# f29h85x_wadi_oper_sss_regs register map
Vendor: Texas Instruments
Peripheral module from a debugger description file (folder C29).
Registers are 32-bit, read-write, no defined reset value unless marked. A register's access mark holds for its fields unless they carry their own. Offsets are as the file gives them; lines under a group give offsets from that group; [hi:lo] are bit positions; {n}, {i} and the like mark numbered series; 'fields as' and 'values as' point back to an identical list; <NAME> marks a mode.

## WADI_OPER_SSS_REGS — WADI OPER SSS Registers
0x00 BASETIMERLOW ro — Read only value for lower word of the base timer.
  [31:0] LOWWORD — Timer value of 31:0 of the base timer.
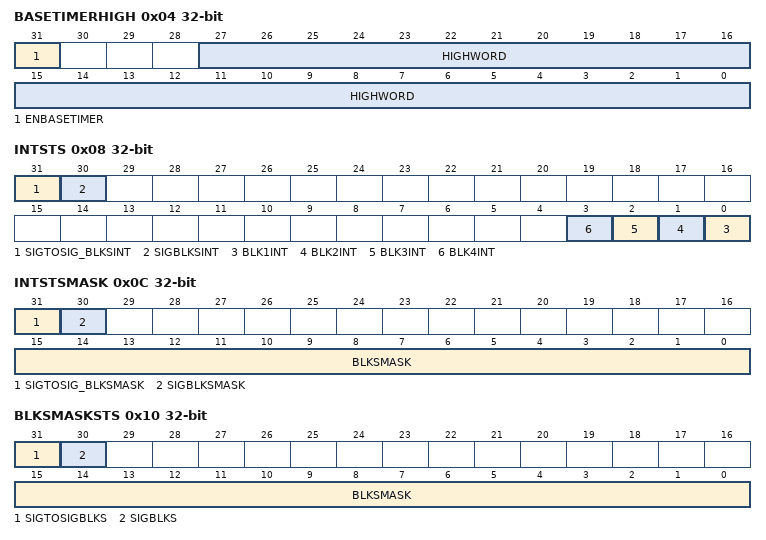
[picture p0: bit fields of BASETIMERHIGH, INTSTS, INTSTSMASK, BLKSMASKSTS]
0x04 BASETIMERHIGH access per field — Upper word of the base timer and trigger to start the timer.
  [31] ENBASETIMER rw — Start base timer trigger
  [27:0] HIGHWORD ro — Upper word of the base timer
0x08 INTSTS ro — Gives the block wise aggregated raw error status that shall trigger the interrupt.
  [31] SIGTOSIG_BLKSINT — ORed int status of mismatch error for all WADI blocks
  [30] SIGBLKSINT — ORed int status of measurement error for all WADI blocks
  [n-1] BLK{n}INT (n=1..4) — Interrupt status by ORing all WADI block errors
0x0C INTSTSMASK — Provides mask for application to suppress or allow a particular block related errors to cause interrupt or not
  [31] SIGTOSIG_BLKSMASK — Line wise mask to propagate interrupt or not
  [30] SIGBLKSMASK — Line wise mask to propagate interrupt or not
  [15:0] BLKSMASK — Line wise mask to propagate interrupt or not
0x10 BLKSMASKSTS ro — This is AND combination of active high indication of block-wise status asserting an interrupt.
  [31] SIGTOSIGBLKS — This is AND of INTSTS and INTSTSMASK
  [30] SIGBLKS — This is AND of INTSTS and INTSTSMASK
  [15:0] BLKSMASK — This is AND of INTSTS and INTSTSMASK
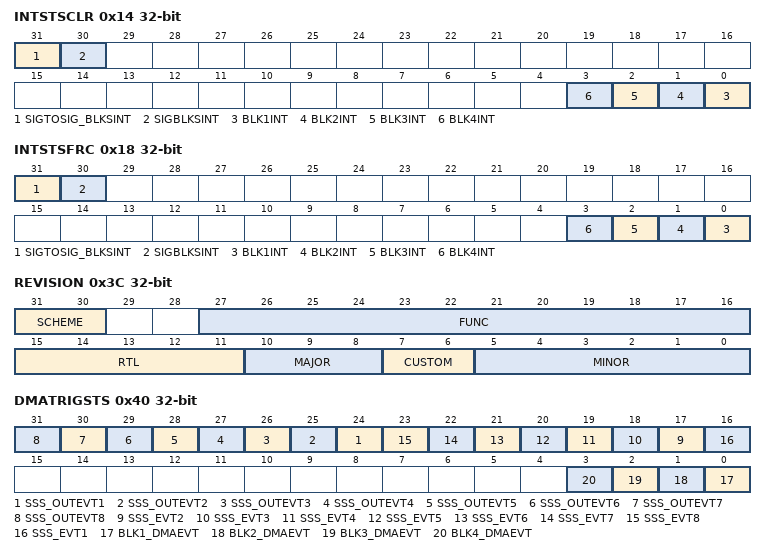
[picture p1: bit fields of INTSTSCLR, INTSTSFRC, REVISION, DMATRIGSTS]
0x14 INTSTSCLR — Provides way for application to clear the interrupt status.
  [31] SIGTOSIG_BLKSINT — Clears the status of all block's INTSTS[SIGTOSIG_BLKSINT]
  [30] SIGBLKSINT — Clears the status of all block's INTSTS[SIGBLKSINT]
  [n-1] BLK{n}INT (n=1..4) — Clears the status of the INTSTS of Block {n}
0x18 INTSTSFRC — Allows emulation of the RIS to raise interrupt in software
  [31] SIGTOSIG_BLKSINT — Allows software force of WADI Block interrupt
  [30] SIGBLKSINT — Allows software force of WADI Block interrupt
  [n-1] BLK{n}INT (n=1..4) — Allows software force of WADI Block interrupt
0x1C SIGSYNCFILTCFG — Each input SIG to be connected through synchroniser or not
  [7:0] BLKS_SIGS_SYNCFILT — Selects SIG is synchronised and filtered or not
0x20 TRIGSYNCFILTCFG — Each trigger to be connected through synchroniser or not
  [7:0] BLKS_TRIG_SYNCFILT — Selects Trigger input is synchronised and filtered or not
0x3C REVISION ro — IP Revision
  [31:30] SCHEME — Defines Scheme for Module
  [27:16] FUNC — Functional Release Number
  [15:11] RTL — Design Release Number
  [10:8] MAJOR — Major Revision Number
  [7:6] CUSTOM — Custom Module Number
  [5:0] MINOR — Minor Revision Number
0x40 DMATRIGSTS — Status of the DMA triggers active
  [n+23] SSS_OUTEVT{n} (n=1..8) — Indicates the SSS output event for DMA trigger
  [n+15] SSS_EVT{n} (n=2..8) — Indicates the SSS Event for DMA trigger
  [16] SSS_EVT1 — Indicates the SSS Event event for DMA trigger
  [n-1] BLK{n}_DMAEVT (n=1..4) — Indicates the WADI Block event for DMA trigger
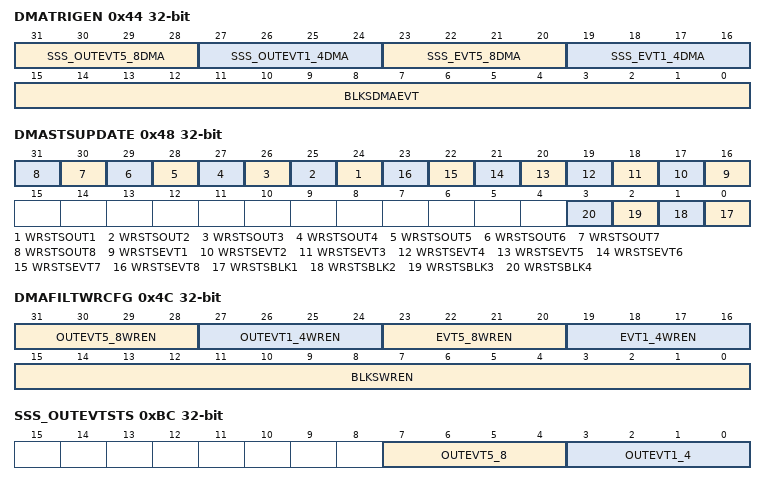
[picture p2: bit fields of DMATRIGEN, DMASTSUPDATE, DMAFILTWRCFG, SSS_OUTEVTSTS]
0x44 DMATRIGEN — Mask to enable individual trigger cause
  [31:28] SSS_OUTEVT5_8DMA — SSS output event 5 to 8 enables for DMA request Trigger
  [27:24] SSS_OUTEVT1_4DMA — SSS output event 1 to 4 enables for DMA request Trigger
  [23:20] SSS_EVT5_8DMA — SSS Event word Set-2 enables for DMA request Trigger
  [19:16] SSS_EVT1_4DMA — SSS Event word Set-1 enables for DMA request Trigger
  [15:0] BLKSDMAEVT — WADI Block event enables for DMA request trigger
0x48 DMASTSUPDATE — Indicates the register set updated post DMA write
  [n+23] WRSTSOUT{n} (n=1..8) — DMA MMR write status of SSS OUTEVT{n}
  [n+15] WRSTSEVT{n} (n=1..8) — DMA MMR write status of SSS Event word
  [n-1] WRSTSBLK{n} (n=1..4) — Status of DMA update for register set of WADI Block
0x4C DMAFILTWRCFG — DMA writes Filter enable for each of WADI and SSS blocks
  [31:28] OUTEVT5_8WREN — Enable for filtered DMA write for SSS output Events 5-8
  [27:24] OUTEVT1_4WREN — Enable for filtered DMA write for SSS output Events 1-4
  [23:20] EVT5_8WREN — Enable for filtered DMA write for SSS Event 5 to 8
  [19:16] EVT1_4WREN — Enable for filtered DMA write for SSS Event 1 to 4
  [15:0] BLKSWREN — Enable for filtered DMA write for WADI Block
0xA4 CFGREGLOCK — Configuration Register Lock
  [0] LOCK
0xA8 CFGREGCOMMIT — Configuration Register Commit
  [0] COMMIT — CONFIG_REG_LOCK Permanent Commit
0xAC OPERREGLOCK — Operating Register Lock
  [0] LOCK
0xB0 OPERREGCOMMIT — Operating Register Commit
  [0] COMMIT — OPER_REG_LOCK Permanent Commit
0xB8 SSS_EVTTRIG — Event trigger word output by WADI instance for SSS
  [7:0] EVTTRIG — SSS start if event trigger matches one of defined EVT1-8
0xBC SSS_OUTEVTSTS — Status of the active event
  [7:4] OUTEVT5_8 — Active seq word status for Second set
  [3:0] OUTEVT1_4 — Active seq word status for first set
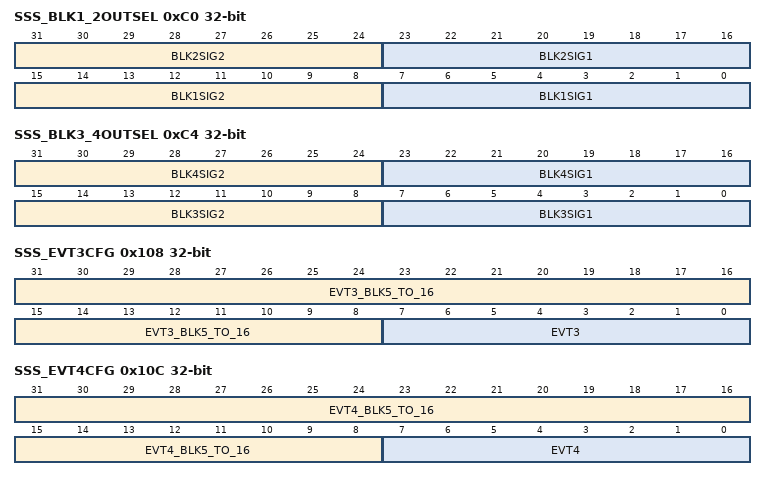
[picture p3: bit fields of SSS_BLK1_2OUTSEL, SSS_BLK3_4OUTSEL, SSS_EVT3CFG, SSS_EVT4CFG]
0xC0 SSS_BLK1_2OUTSEL — Mux select word for outputs 0-3
  [31:24] BLK2SIG2 — Maps the OUTEVTn associated with BLK1:SIG2
  [23:16] BLK2SIG1 — Maps the OUTEVTn associated with BLK1:SIG1
  [15:8] BLK1SIG2 — Maps the OUTEVTn associated with BLK0:SIG2
  [7:0] BLK1SIG1 — Maps the OUTEVTn associated with BLK0:SIG1
0xC4 SSS_BLK3_4OUTSEL — Mux select word for outputs 4-7
  [31:24] BLK4SIG2 — Maps the OUTEVTn associated with BLK3:SIG2
  [23:16] BLK4SIG1 — Maps the OUTEVTn associated with BLK3:SIG1
  [15:8] BLK3SIG2 — Maps the OUTEVTn associated with BLK2:SIG2
  [7:0] BLK3SIG1 — Maps the OUTEVTn associated with BLK2:SIG1
0xE0 SSS_OUTEVT1LINKCFG — Output event1 Link configuration
  [7:0] OUTEVT1LINK — Links output events (OUTEVTs) as per one hot encoding
{0xDC+4i} SSS_OUTEVT{i}LINKCFG (i=2..7) — Output event{i} link configuration
  [7:0] OUTEVT{i}LINK — Links output events (OUTEVTs) as per one hot encoding
0xFC SSS_OUTEVT8LINKCFG — Output event8 link configuration
  [7:0] OUT8LINK — Links output events (OUTEVTs) as per one hot encoding
0x100 SSS_EVT1CFG — Event1 that compares to trigger word SSS_EVTTRIG
  [7:0] EVT1 — First event compare configuration
0x104 SSS_EVT2CFG — Event2 that compares to trigger word SSS_EVTTRIG
  [7:0] EVT2 — Second word compare value configuration
0x108 SSS_EVT3CFG — Event3 that compares to trigger word SSS_EVTTRIG
  [31:8] EVT3_BLK5_TO_16 — Third word compare value configuration
  [7:0] EVT3 — Third word compare value configuration
0x10C SSS_EVT4CFG — Event4 that compares to trigger word SSS_EVTTRIG
  [31:8] EVT4_BLK5_TO_16 — Fourth word compare value configuration
  [7:0] EVT4 — Fourth word compare value configuration
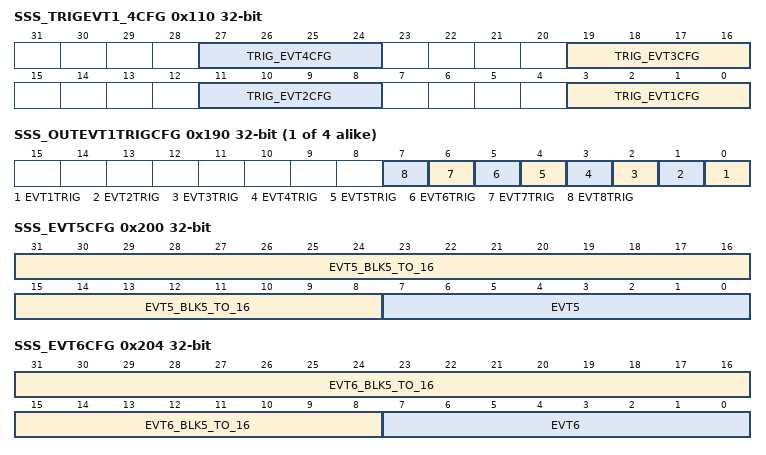
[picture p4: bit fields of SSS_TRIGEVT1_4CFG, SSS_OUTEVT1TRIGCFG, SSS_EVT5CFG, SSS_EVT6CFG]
0x110 SSS_TRIGEVT1_4CFG — Configuration for using trigger word in specific manner
  [8n-5:8n-8] TRIG_EVT{n}CFG (n=1..4) — Selects action associated with event {n}
{0x17C+4i} SSS_BLKSOUTEVT{i}CFG (i=1..4) — Output event{i} to be applied for output
  [7:0] OUTEVT{i} — Output configuration on event {i}
{0x18C+4i} SSS_OUTEVT{i}TRIGCFG (i=1..4) — Output event{i} configuration for triggers, link
  [n-1] EVT{n}TRIG (n=1..8) — Sets OUTEVT{i} based on Event {n} Trigger
{0x19C+4i} SSS_OUTEVT{i}DUR (i=1..4) — Output event{i} configuration of delays
  [23:0] TIME — Duration time for application of OUTEVT{i}
0x200 SSS_EVT5CFG — Event5 that compares to trigger word SSS_EVTTRIG
  [31:8] EVT5_BLK5_TO_16 — Fifth word compare value configuration
  [7:0] EVT5 — Fifth word compare value configuration
0x204 SSS_EVT6CFG — Event6 that compares to trigger word SSS_EVTTRIG
  [31:8] EVT6_BLK5_TO_16 — Sixth word compare value configuration
  [7:0] EVT6 — Sixth word compare value configuration
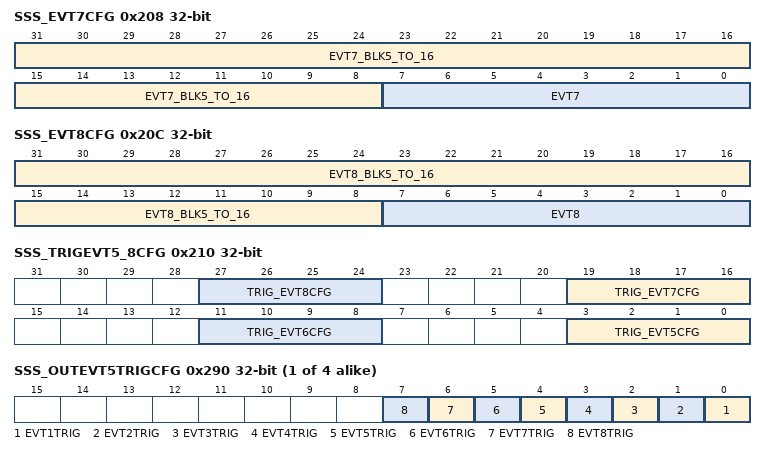
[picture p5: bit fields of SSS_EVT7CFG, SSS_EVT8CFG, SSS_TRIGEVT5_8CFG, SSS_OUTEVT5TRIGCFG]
0x208 SSS_EVT7CFG — Event7 that compares to trigger word SSS_EVTTRIG
  [31:8] EVT7_BLK5_TO_16 — Seventh word compare value configuration
  [7:0] EVT7 — Seventh word compare value configuration
0x20C SSS_EVT8CFG — Event8 that compares to trigger word SSS_EVTTRIG
  [31:8] EVT8_BLK5_TO_16 — Eighth word compare value configuration
  [7:0] EVT8 — Eighth word compare value configuration
0x210 SSS_TRIGEVT5_8CFG — Configuration for using trigger word in specific manner
  [8n-37:8n-40] TRIG_EVT{n}CFG (n=5..8) — Selects action associated with event {n}
{0x26C+4i} SSS_BLKSOUTEVT{i}CFG (i=5..8) — Output event{i} to be applied for output
  [7:0] OUTEVT{i} — Output configuration on event {i}
{0x27C+4i} SSS_OUTEVT{i}TRIGCFG (i=5..8) — Output event{i} configuration for triggers, link
  fields as SSS_OUTEVT1TRIGCFG
{0x28C+4i} SSS_OUTEVT{i}DUR (i=5..8) — Output event{i} configuration of delays
  [23:0] TIME — Duration time for application of OUTEVT{i}
0x2C8 PARTEST — Enables parity test
  [3:0] TESTEN — Parity test enable configuration
